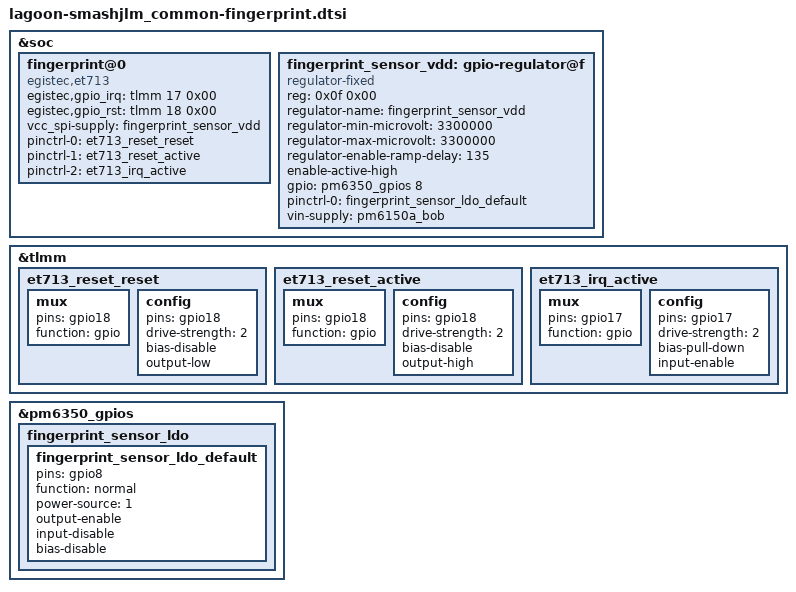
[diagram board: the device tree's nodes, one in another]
// SPDX-License-Identifier: GPL-2.0-only
/*
 * Copyright (c) 2018-2019, The Linux Foundation. All rights reserved.
 */

&soc{
	fingerprint@0 {
		compatible = "egistec,et713";
		egistec,gpio_irq = <&tlmm 17 0x00>;
		egistec,gpio_rst = <&tlmm 18 0x00>;
		vcc_spi-supply = <&fingerprint_sensor_vdd>;
		pinctrl-names = "et713_reset_reset",
			"et713_reset_active",
			"et713_irq_active";
		pinctrl-0 = <&et713_reset_reset>;
		pinctrl-1 = <&et713_reset_active>;
		pinctrl-2 = <&et713_irq_active>;
		status = "ok";
	};

	fingerprint_sensor_vdd: gpio-regulator@f {
		compatible = "regulator-fixed";
		reg = <0x0f 0x00>;
		regulator-name = "fingerprint_sensor_vdd";
		regulator-min-microvolt = <3300000>;
		regulator-max-microvolt = <3300000>;
		regulator-enable-ramp-delay = <135>; // TBD
		enable-active-high;
		gpio = <&pm6350_gpios 8 0x00>;
		pinctrl-names = "default";
		pinctrl-0 = <&fingerprint_sensor_ldo_default>;
		vin-supply = <&pm6150a_bob>;
	};
};

&tlmm {
	et713_reset_reset: et713_reset_reset {
		mux {
			pins = "gpio18";
			function = "gpio";
		};
		config {
			pins = "gpio18";
			drive-strength = <2>;
			bias-disable;
			output-low;
		};
	};

	et713_reset_active: et713_reset_active {
		mux {
			pins = "gpio18";
			function = "gpio";
		};
		config {
			pins = "gpio18";
			drive-strength = <2>;
			bias-disable;
			output-high;
		};
	};

	et713_irq_active: et713_irq_active {
		mux {
			pins = "gpio17";
			function = "gpio";
		};
		config {
			pins = "gpio17";
			drive-strength = <2>;
			bias-pull-down;
			input-enable;
		};
	};
};

&pm6350_gpios {
	fingerprint_sensor_ldo {
		fingerprint_sensor_ldo_default: fingerprint_sensor_ldo_default {
			pins = "gpio8";
			function = "normal";
			power-source = <1>; /* 1.8V input supply */
			output-enable;
			input-disable;
			bias-disable;
		};
	};

};
